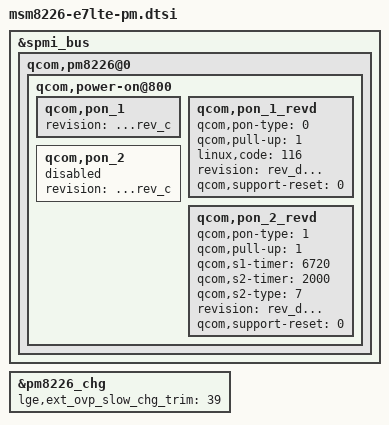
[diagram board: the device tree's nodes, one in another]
/* Copyright (c) 2012, Code Aurora Forum. All rights reserved.
 *
 * This program is free software; you can redistribute it and/or modify
* it under the terms of the GNU General Public License version 2 and
* only version 2 as published by the Free Software Foundation.
*
* This program is distributed in the hope that it will be useful,
* but WITHOUT ANY WARRANTY; without even the implied warranty of
* MERCHANTABILITY or FITNESS FOR A PARTICULAR PURPOSE.  See the
* GNU General Public License for more details.
*/

&spmi_bus {
	qcom,pm8226@0 {
		qcom,power-on@800{
			qcom,pon_1 {
				revision = "...rev_c";
			};
			qcom,pon_1_revd {
				qcom,pon-type = <0>;
				qcom,pull-up = <1>;
				linux,code = <116>;
				revision = "rev_d...";
				qcom,support-reset = <0>;
			};
			qcom,pon_2 {
				revision = "...rev_c";
				status = "disable";
			};
			qcom,pon_2_revd {
				qcom,pon-type = <1>;
				qcom,pull-up = <1>;
				qcom,s1-timer = <6720>;
				qcom,s2-timer = <2000>;
				qcom,s2-type = <7>;
				status = "ok";
				revision = "rev_d...";
				qcom,support-reset = <0>;
			};
		};
	};
};
&pm8226_chg {
	lge,ext_ovp_slow_chg_trim = <39>;
};
